# R7FA0E107 register map
Vendor: Renesas Electronics Corporation; Series: RA0; File version: 1.10.00
CPU: CM23 r1p0, little endian, no MPU, no FPU, VTOR, 2 interrupt priority bits, 64 interrupts
Registers are 16-bit, read-write, reset 0x0 unless marked. A register's access mark holds for its fields unless they carry their own. Offsets are from the block's base; [hi:lo] are bit positions; {n}, {i} and the like mark numbered series; 'fields as' and 'values as' point back to an identical list.

## PORT4 — Port 4 Control
Base 0x400A0080
0x00 PODR4 — Port 4 Output Data Register
  [7] PODR07 — P407 Output Data
0x02 PDR4 — Port 4 Direction Register
  [7] PDR07 — P407 Direction
0x06 PIDR4 ro (reset mask 0xFF7F) — Port 4 State Register
  [7] PIDR07 — P407 State
0x08 PORR4 wo — Port 4 Output Reset Register
  [7] PORR07 — P407 Output Reset
0x0A POSR4 wo — Port 4 Output Set Register
  [7] POSR07 — P407 Output Set

## PORT9 — Port 9 Control
Base 0x400A0120
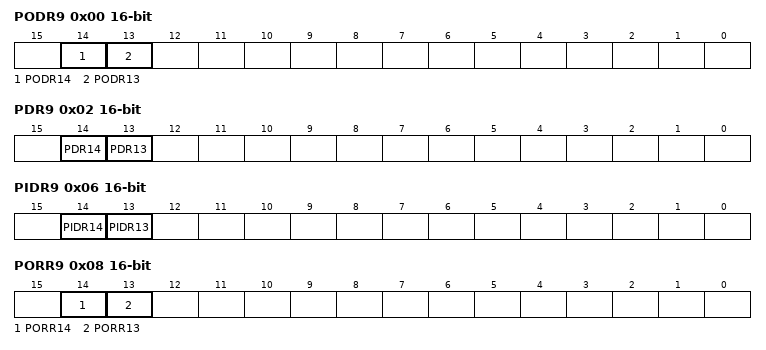
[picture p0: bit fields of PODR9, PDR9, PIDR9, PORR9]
0x00 PODR9 — Port 9 Output Data Register
  [14] PODR14 — P914 Output Data
  [13] PODR13 — P913 Output Data
0x02 PDR9 — Port 9 Direction Register
  [14] PDR14 — P914 Direction
  [13] PDR13 — P913 Direction
0x06 PIDR9 ro (reset mask 0x9FFF) — Port 9 State Register
  [14] PIDR14 — P914 State
  [13] PIDR13 — P913 State
0x08 PORR9 wo — Port 9 Output Reset Register
  [14] PORR14 — P914 Output Reset
  [13] PORR13 — P913 Output Reset
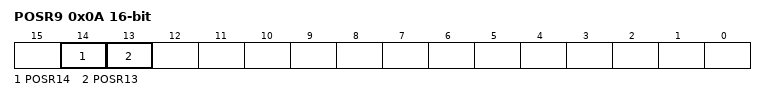
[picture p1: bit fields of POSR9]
0x0A POSR9 wo — Port 9 Output Set Register
  [14] POSR14 — P914 Output Set
  [13] POSR13 — P913 Output Set

## PFS_A — Pmn Pin Function Select
Base 0x400A0200
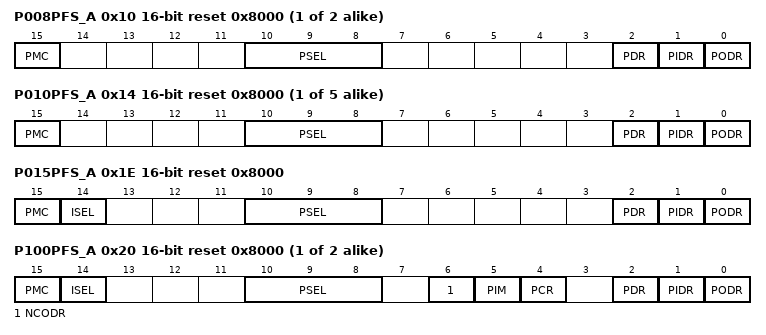
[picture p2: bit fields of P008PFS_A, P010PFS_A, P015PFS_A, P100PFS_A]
{0x0+2i} P00{i}PFS_A (i=8..9) reset 0x8000 — Port 00{i} Pin Function Select Register
  [15] PMC — Pin mode control
  [10:8] PSEL — These bits select the peripheral function. For individual pin functions, see the associated tables in this chapter.
  [2] PDR
  [1] PIDR ro — Pmn State
  [0] PODR — Port Output Data
{0x0+2i} P0{i}PFS_A (i=10..14) reset 0x8000 — Port 0{i} Pin Function Select Register
  fields as P008PFS_A
0x1E P015PFS_A reset 0x8000 — Port 015 Pin Function Select Register
  [15] PMC — Pin mode control
  [14] ISEL — IRQ Input Enable
  [10:8] PSEL — These bits select the peripheral function. For individual pin functions, see the associated tables in this chapter.
  [2] PDR
  [1] PIDR ro — Pmn State
  [0] PODR — Port Output Data
{0x20+2i} P10{i}PFS_A (i=0..1) reset 0x8000 — Port 10{i} Pin Function Select Register
  [15] PMC — Pin mode control
  [14] ISEL — IRQ Input Enable
  [10:8] PSEL — These bits select the peripheral function. For individual pin functions, see the associated tables in this chapter.
  [6] NCODR
  [5] PIM
  [4] PCR
  [2] PDR
  [1] PIDR ro — Pmn State
  [0] PODR — Port Output Data
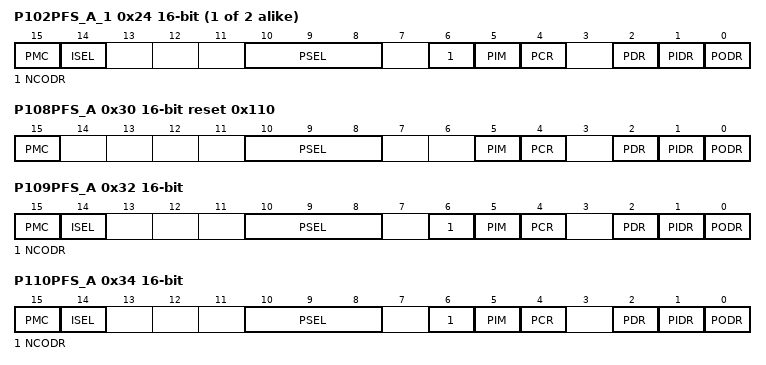
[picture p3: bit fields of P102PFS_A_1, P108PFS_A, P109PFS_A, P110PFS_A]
{0x20+2i} P10{i}PFS_A_1 (i=2..3) (reset mask 0xFFFD) — Port 10{i} Pin Function Select Register
  fields as P100PFS_A
0x30 P108PFS_A reset 0x110 (reset mask 0xFFFD) — Port 108 Pin Function Select Register
  [15] PMC — Pin mode control
  [10:8] PSEL — These bits select the peripheral function. For individual pin functions, see the associated tables in this chapter.
  [5] PIM
  [4] PCR
  [2] PDR
  [1] PIDR ro — Pmn State
  [0] PODR — Port Output Data
0x32 P109PFS_A (reset mask 0xFFFD) — Port 109 Pin Function Select Register
  fields as P100PFS_A
0x34 P110PFS_A (reset mask 0xFFFD) — Port 110 Pin Function Select Register
  fields as P100PFS_A
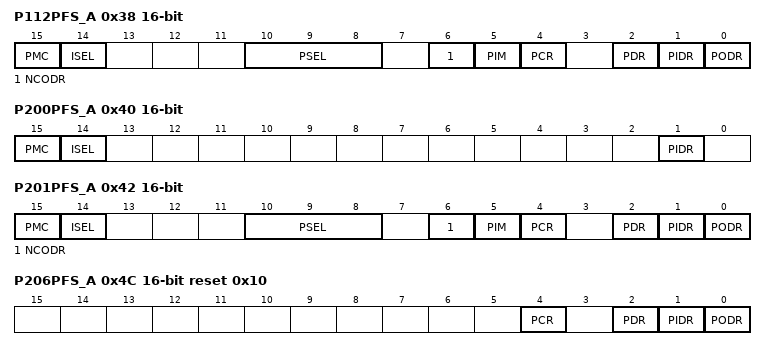
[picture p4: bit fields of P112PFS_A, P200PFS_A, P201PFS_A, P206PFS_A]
0x38 P112PFS_A (reset mask 0xFFFD) — Port 112 Pin Function Select Register
  fields as P100PFS_A
0x40 P200PFS_A (reset mask 0xFFFD) — Port 200 Pin Function Select Register
  [15] PMC — Pin mode control
  [14] ISEL — IRQ Input Enable
  [1] PIDR ro — Pmn State
0x42 P201PFS_A (reset mask 0xFFFD) — Port 201 Pin Function Select Register
  fields as P100PFS_A
0x4C P206PFS_A reset 0x10 (reset mask 0xFFFD) — Port 206 Pin Function Select Register
  [4] PCR
  [2] PDR
  [1] PIDR ro — Pmn State
  [0] PODR — Port Output Data
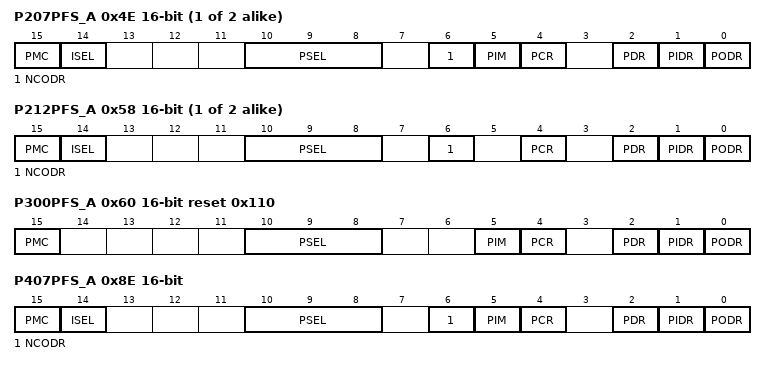
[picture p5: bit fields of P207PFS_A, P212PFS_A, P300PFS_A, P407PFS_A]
{0x40+2i} P20{i}PFS_A (i=7..8) (reset mask 0xFFFD) — Port 20{i} Pin Function Select Register
  fields as P100PFS_A
{0x40+2i} P2{i}PFS_A (i=12..13) (reset mask 0xFFFD) — Port 2{i} Pin Function Select Register
  [15] PMC — Pin mode control
  [14] ISEL — IRQ Input Enable
  [10:8] PSEL — These bits select the peripheral function. For individual pin functions, see the associated tables in this chapter.
  [6] NCODR
  [4] PCR
  [2] PDR
  [1] PIDR ro — Pmn State
  [0] PODR — Port Output Data
{0x40+2i} P2{i}PFS_A_1 (i=14..15) (reset mask 0xFFFD) — Port 2{i} Pin Function Select Register
  [1] PIDR ro — Pmn State
0x60 P300PFS_A reset 0x110 (reset mask 0xFFFD) — Port 300 Pin Function Select Register
  fields as P108PFS_A
0x8E P407PFS_A (reset mask 0xFFFD) — Port 407 Pin Function Select Register
  fields as P100PFS_A
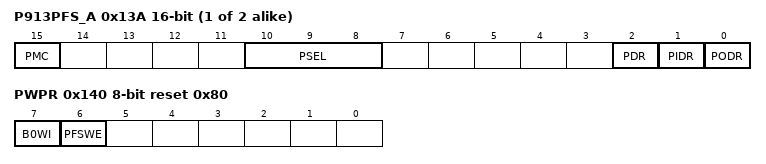
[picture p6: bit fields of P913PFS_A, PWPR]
{0x120+2i} P9{i}PFS_A (i=13..14) (reset mask 0xFFFD) — Port 9{i} Pin Function Select Register
  [15] PMC — Pin Mode Control
  [10:8] PSEL — Peripheral Select
  [2] PDR — P9n Direction
  [1] PIDR ro — P9n State
  [0] PODR — P9n Output Data
0x140 PWPR 8-bit reset 0x80 — Write,Protect Register
  [7] B0WI — PFSWE Bit Write Disable
  [6] PFSWE — PmnPFS_A Register Write Enable
